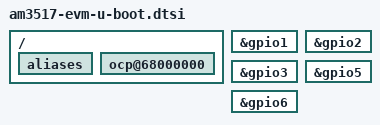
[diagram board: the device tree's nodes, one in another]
// SPDX-License-Identifier: GPL-2.0+
/*
 * Copyright (C) 2017
 * Logic PD - http://www.logicpd.com
 */

#include "omap3-u-boot.dtsi"

/ {
	aliases {
		/delete-property/ serial0;
		/delete-property/ serial1;
	};

	ocp@68000000 {
		/delete-node/ bandgap@48002524;
	};
};

&gpio1 {
	/delete-property/ u-boot,dm-spl;
};

&gpio2 {
	/delete-property/ u-boot,dm-spl;
};

&gpio3 {
	/delete-property/ u-boot,dm-spl;
};

&gpio5 {
	/delete-property/ u-boot,dm-spl;
};

&gpio6 {
	/delete-property/ u-boot,dm-spl;
};

/delete-node/ &uart1;
/delete-node/ &uart2;
/delete-node/ &mmc2;
/delete-node/ &mmc3;
